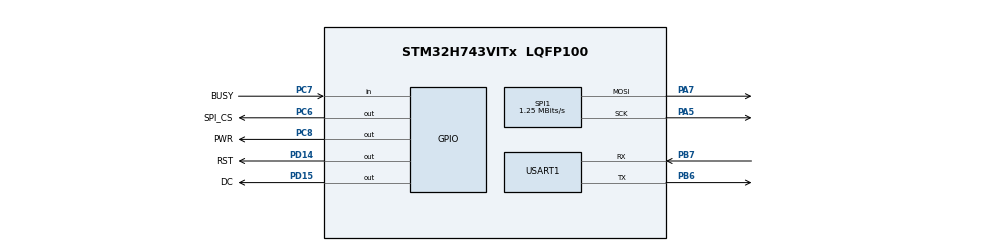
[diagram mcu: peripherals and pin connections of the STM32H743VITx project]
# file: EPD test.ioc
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CORTEX_M7.default_mode_Activation=1
Mcu.Family=STM32H7
Mcu.Name=STM32H743VITx
Mcu.Package=LQFP100
NVIC.PriorityGroup=NVIC_PRIORITYGROUP_4
PA5.Mode=TX_Only_Simplex_Unidirect_Master
PA5.Signal=SPI1_SCK
PA7.Mode=TX_Only_Simplex_Unidirect_Master
PA7.Signal=SPI1_MOSI
PB6.Mode=Asynchronous
PB6.Signal=USART1_TX
PB7.Mode=Asynchronous
PB7.Signal=USART1_RX
PC14-OSC32_IN\ (OSC32_IN).Mode=LSE-External-Oscillator
PC14-OSC32_IN\ (OSC32_IN).Signal=RCC_OSC32_IN
PC15-OSC32_OUT\ (OSC32_OUT).Mode=LSE-External-Oscillator
PC15-OSC32_OUT\ (OSC32_OUT).Signal=RCC_OSC32_OUT
PC6.GPIO_Label=SPI_CS
PC6.Signal=GPIO_Output
PC7.GPIO_Label=BUSY
PC7.Signal=GPIO_Input
PC8.GPIO_Label=PWR
PC8.Signal=GPIO_Output
PD14.GPIO_Label=RST
PD14.Signal=GPIO_Output
PD15.GPIO_Label=DC
PD15.Signal=GPIO_Output
PH0-OSC_IN\ (PH0).Mode=HSE-External-Oscillator
PH0-OSC_IN\ (PH0).Signal=RCC_OSC_IN
PH1-OSC_OUT\ (PH1).Mode=HSE-External-Oscillator
PH1-OSC_OUT\ (PH1).Signal=RCC_OSC_OUT
ProjectManager.HeapSize=0x200
ProjectManager.StackSize=0x400
ProjectManager.TargetToolchain=STM32CubeIDE
RCC.ADCFreq_Value=129000000
RCC.APB1Freq_Value=64000000
RCC.APB2Freq_Value=64000000
RCC.APB3Freq_Value=64000000
RCC.APB4Freq_Value=64000000
RCC.CortexFreq_Value=64000000
RCC.DIVM1=4
RCC.DIVN1=10
RCC.HCLKFreq_Value=64000000
RCC.PLLFRACN=0
RCC.SYSCLKFreq_VALUE=64000000
RCC.USBFreq_Value=80000000
SPI1.BaudRatePrescaler=SPI_BAUDRATEPRESCALER_64
SPI1.CalculateBaudRate=1.25 MBits/s
SPI1.DataSize=SPI_DATASIZE_8BIT
SPI1.Direction=SPI_DIRECTION_2LINES_TXONLY
SPI1.Mode=SPI_MODE_MASTER
SPI1.VirtualType=VM_MASTER
USART1.VirtualMode-Asynchronous=VM_ASYNC
VP_MEMORYMAP_VS_MEMORYMAP.Mode=CurAppReg
board=custom

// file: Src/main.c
/* USER CODE BEGIN Header */
/**
  ******************************************************************************
  * @file           : main.c
  * @brief          : Main program body
  ******************************************************************************
  * @attention
  *
  * <h2><center>&copy; Copyright (c) 2021 STMicroelectronics.
  * All rights reserved.</center></h2>
  *
  * This software component is licensed by ST under BSD 3-Clause license,
  * the "License"; You may not use this file except in compliance with the
  * License. You may obtain a copy of the License at:
  *                        opensource.org/licenses/BSD-3-Clause
  *
  ******************************************************************************
  */
/* USER CODE END Header */
#include "main.h"
#include "spi.h"
#include "usart.h"
#include "gpio.h"

/* USER CODE BEGIN Includes */
#include "EPD_Test.h"

/* USER CODE END Includes */

/* USER CODE BEGIN PV */
/* Private variables ---------------------------------------------------------*/

/* USER CODE END PV */

void SystemClock_Config(void);
static void MPU_Config(void);
/* USER CODE BEGIN PFP */
/* Private function prototypes -----------------------------------------------*/

/* USER CODE END PFP */

int main(void)
{

  /* MPU Configuration--------------------------------------------------------*/
  MPU_Config();

  /* MCU Configuration--------------------------------------------------------*/

  /* Reset of all peripherals, Initializes the Flash interface and the Systick. */
  HAL_Init();

  /* Configure the system clock */
  SystemClock_Config();

  /* Initialize all configured peripherals */
  MX_GPIO_Init();
  MX_SPI1_Init();
  MX_USART1_UART_Init();
  /* USER CODE BEGIN 2 */

  EPD_test();

  /* USER CODE END 2 */

  /* Infinite loop */
    while (1) {

    /* USER CODE BEGIN 3 */
			HAL_Delay(10000);

    }
  /* USER CODE END 3 */
}

void SystemClock_Config(void)
{
  RCC_OscInitTypeDef RCC_OscInitStruct = {0};
  RCC_ClkInitTypeDef RCC_ClkInitStruct = {0};

  /** Supply configuration update enable
  */
  HAL_PWREx_ConfigSupply(PWR_LDO_SUPPLY);

  /** Configure the main internal regulator output voltage
  */
  __HAL_PWR_VOLTAGESCALING_CONFIG(PWR_REGULATOR_VOLTAGE_SCALE3);

  while(!__HAL_PWR_GET_FLAG(PWR_FLAG_VOSRDY)) {}

  /** Initializes the RCC Oscillators according to the specified parameters
  * in the RCC_OscInitTypeDef structure.
  */
  RCC_OscInitStruct.OscillatorType = RCC_OSCILLATORTYPE_HSI;
  RCC_OscInitStruct.HSIState = RCC_HSI_DIV1;
  RCC_OscInitStruct.HSICalibrationValue = RCC_HSICALIBRATION_DEFAULT;
  RCC_OscInitStruct.PLL.PLLState = RCC_PLL_ON;
  RCC_OscInitStruct.PLL.PLLSource = RCC_PLLSOURCE_HSI;
  RCC_OscInitStruct.PLL.PLLM = 4;
  RCC_OscInitStruct.PLL.PLLN = 10;
  RCC_OscInitStruct.PLL.PLLP = 2;
  RCC_OscInitStruct.PLL.PLLQ = 2;
  RCC_OscInitStruct.PLL.PLLR = 2;
  RCC_OscInitStruct.PLL.PLLRGE = RCC_PLL1VCIRANGE_3;
  RCC_OscInitStruct.PLL.PLLVCOSEL = RCC_PLL1VCOMEDIUM;
  RCC_OscInitStruct.PLL.PLLFRACN = 0;
  if (HAL_RCC_OscConfig(&RCC_OscInitStruct) != HAL_OK)
  {
    Error_Handler();
  }

  /** Initializes the CPU, AHB and APB buses clocks
  */
  RCC_ClkInitStruct.ClockType = RCC_CLOCKTYPE_HCLK|RCC_CLOCKTYPE_SYSCLK
                              |RCC_CLOCKTYPE_PCLK1|RCC_CLOCKTYPE_PCLK2
                              |RCC_CLOCKTYPE_D3PCLK1|RCC_CLOCKTYPE_D1PCLK1;
  RCC_ClkInitStruct.SYSCLKSource = RCC_SYSCLKSOURCE_HSI;
  RCC_ClkInitStruct.SYSCLKDivider = RCC_SYSCLK_DIV1;
  RCC_ClkInitStruct.AHBCLKDivider = RCC_HCLK_DIV1;
  RCC_ClkInitStruct.APB3CLKDivider = RCC_APB3_DIV1;
  RCC_ClkInitStruct.APB1CLKDivider = RCC_APB1_DIV1;
  RCC_ClkInitStruct.APB2CLKDivider = RCC_APB2_DIV1;
  RCC_ClkInitStruct.APB4CLKDivider = RCC_APB4_DIV1;

  if (HAL_RCC_ClockConfig(&RCC_ClkInitStruct, FLASH_LATENCY_1) != HAL_OK)
  {
    Error_Handler();
  }
}

 /* MPU Configuration */

void MPU_Config(void)
{
  MPU_Region_InitTypeDef MPU_InitStruct = {0};

  /* Disables the MPU */
  HAL_MPU_Disable();

  /** Initializes and configures the Region and the memory to be protected
  */
  MPU_InitStruct.Enable = MPU_REGION_ENABLE;
  MPU_InitStruct.Number = MPU_REGION_NUMBER0;
  MPU_InitStruct.BaseAddress = 0x0;
  MPU_InitStruct.Size = MPU_REGION_SIZE_4GB;
  MPU_InitStruct.SubRegionDisable = 0x87;
  MPU_InitStruct.TypeExtField = MPU_TEX_LEVEL0;
  MPU_InitStruct.AccessPermission = MPU_REGION_NO_ACCESS;
  MPU_InitStruct.DisableExec = MPU_INSTRUCTION_ACCESS_DISABLE;
  MPU_InitStruct.IsShareable = MPU_ACCESS_SHAREABLE;
  MPU_InitStruct.IsCacheable = MPU_ACCESS_NOT_CACHEABLE;
  MPU_InitStruct.IsBufferable = MPU_ACCESS_NOT_BUFFERABLE;

  HAL_MPU_ConfigRegion(&MPU_InitStruct);
  /* Enables the MPU */
  HAL_MPU_Enable(MPU_PRIVILEGED_DEFAULT);

}

void Error_Handler(void)
{
  /* USER CODE BEGIN Error_Handler_Debug */
    /* User can add his own implementation to report the HAL error return state */
    while(1) {
			printf("_Error_Handler\r\n");
    }
  /* USER CODE END Error_Handler_Debug */
}
